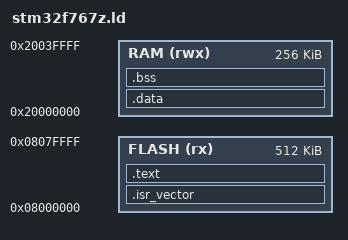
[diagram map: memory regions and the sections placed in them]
/* Linker script for STM32F767ZIT */

MEMORY
{
  FLASH (rx)  : ORIGIN = 0x08000000, LENGTH = 512K
  RAM   (rwx) : ORIGIN = 0x20000000, LENGTH = 256K
}

SECTIONS
{
  .isr_vector :
  {
    KEEP(*(.isr_vector))
  } > FLASH

  .text :
  {
    *(.text*)
    *(.rodata*)
    _etext = .;
  } > FLASH

  .data : AT (_etext)
  {
    _sdata = .;
    *(.data*)
    _edata = .;
  } > RAM

  .bss :
  {
    _sbss = .;
    *(.bss*)
    *(COMMON)
    _ebss = .;
  } > RAM

  _estack = ORIGIN(RAM) + LENGTH(RAM);
}

